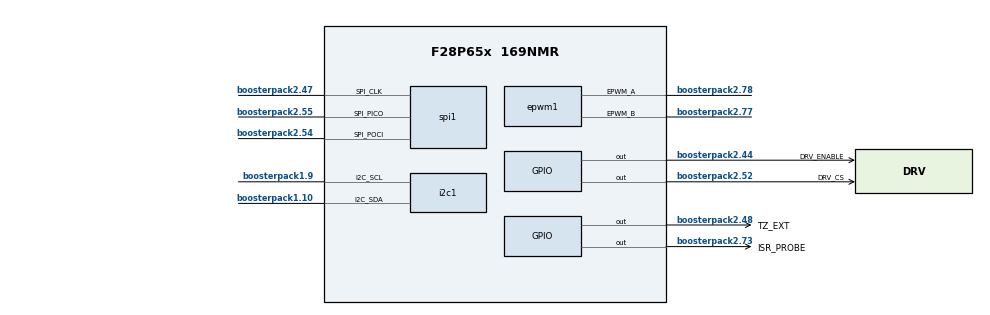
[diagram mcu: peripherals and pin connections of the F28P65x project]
/**
 *
 * @cliArgs --board "/boards/LAUNCHXL_F28P65X" --device "F28P65x" --part "F28P65x_169NMR" --package "169NMR" --context "CPU1" --product "C2000WARE@26.01.00.00"
 * @versions {"tool":"1.28.0+4696"}
 */

/**
 * Import the modules used in this configuration.
 */
const adc            = scripting.addModule("/driverlib/adc.js", {}, false);
const adc1           = adc.addInstance();
const adc2           = adc.addInstance();
const adc3           = adc.addInstance();
const analog         = scripting.addModule("/driverlib/analog.js", {}, false);
const analog1        = analog.addInstance();
const asysctl        = scripting.addModule("/driverlib/asysctl.js");
const led            = scripting.addModule("/driverlib/board_components/led", {}, false);
const led1           = led.addInstance();
const led2           = led.addInstance();
const cmpss          = scripting.addModule("/driverlib/cmpss.js", {}, false);
const cmpss1         = cmpss.addInstance();
const cmpss2         = cmpss.addInstance();
const cputimer       = scripting.addModule("/driverlib/cputimer.js", {}, false);
const cputimer1      = cputimer.addInstance();
const device_support = scripting.addModule("/driverlib/device_support.js");
const epwm           = scripting.addModule("/driverlib/epwm.js", {}, false);
const epwm1          = epwm.addInstance();
const epwm2          = epwm.addInstance();
const epwm3          = epwm.addInstance();
const epwmxbar       = scripting.addModule("/driverlib/epwmxbar.js", {}, false);
const epwmxbar1      = epwmxbar.addInstance();
const gpio           = scripting.addModule("/driverlib/gpio.js", {}, false);
const gpio1          = gpio.addInstance();
const gpio2          = gpio.addInstance();
const gpio3          = gpio.addInstance();
const gpio4          = gpio.addInstance();
const i2c            = scripting.addModule("/driverlib/i2c.js", {}, false);
const i2c1           = i2c.addInstance();
const spi            = scripting.addModule("/driverlib/spi.js", {}, false);
const spi1           = spi.addInstance();
const sysctl         = scripting.addModule("/driverlib/sysctl.js");

/**
 * Write custom configuration values to the imported modules.
 */
adc1.$name               = "myADC0";
adc1.adcClockPrescaler   = "ADC_CLK_DIV_4_0";
adc1.soc0Trigger         = "ADC_TRIGGER_EPWM1_SOCA";
adc1.soc0SampleWindow    = 20;
adc1.useInterrupts       = false;
adc1.enableTDMA          = false;
adc1.enabledInts         = ["ADC_INT_NUMBER1"];
adc1.enableInterrupt1    = true;
adc1.interruptPulseMode  = "ADC_PULSE_END_OF_CONV";
adc1.soc0Channel         = "ADC_CH_ADCIN15";
adc1.soc1Channel         = "ADC_CH_ADCIN8";
adc1.soc2Channel         = "ADC_CH_ADCIN10";
adc1.soc1Trigger         = "ADC_TRIGGER_EPWM1_SOCA";
adc1.soc2Trigger         = "ADC_TRIGGER_EPWM1_SOCA";
adc1.soc1SampleWindow    = 20;
adc1.soc2SampleWindow    = 20;
adc1.enabledSOCs         = ["ADC_SOC_NUMBER0","ADC_SOC_NUMBER1","ADC_SOC_NUMBER2","ADC_SOC_NUMBER3"];
adc1.interrupt1SOCSource = "ADC_INT_TRIGGER_EOC3";
adc1.soc3Channel         = "ADC_CH_ADCIN5";
adc1.soc3Trigger         = "ADC_TRIGGER_EPWM1_SOCA";
adc1.soc3SampleWindow    = 20;

adc2.$name             = "myADC1";
adc2.adcBase           = "ADCB_BASE";
adc2.adcClockPrescaler = "ADC_CLK_DIV_4_0";
adc2.useInterrupts     = false;
adc2.enabledSOCs       = ["ADC_SOC_NUMBER0","ADC_SOC_NUMBER1"];
adc2.soc0Channel       = "ADC_CH_ADCIN3";
adc2.soc1Channel       = "ADC_CH_ADCIN6";
adc2.soc0Trigger       = "ADC_TRIGGER_EPWM1_SOCA";
adc2.soc1Trigger       = "ADC_TRIGGER_EPWM1_SOCA";
adc2.soc0SampleWindow  = 20;
adc2.soc1SampleWindow  = 20;

adc3.$name                      = "myADC2";
adc3.adcBase                    = "ADCC_BASE";
adc3.adcClockPrescaler          = "ADC_CLK_DIV_4_0";
adc3.useInterrupts              = false;
adc3.enabledSOCs                = ["ADC_SOC_NUMBER0"];
adc3.soc0Channel                = "ADC_CH_ADCIN5";
adc3.soc0Trigger                = "ADC_TRIGGER_EPWM1_SOCA";
adc3.soc0SampleWindow           = 20;
adc3.enabledPPBs                = ["ADC_PPB_NUMBER1"];
adc3.ppb1Name                   = "PHASE_C_CURRENT_LIMIT";
adc3.ppb1EventEnable            = ["ADC_EVT_TRIPHI","ADC_EVT_TRIPLO"];
adc3.ppb1HighTripLimit          = 3584;
adc3.ppb1LowTripLimit           = 512;
adc3.ppb1EnablePPBEventCBCClear = true;

led1.$hardware              = system.deviceData.board.components.LED4;
led1.$name                  = "LED_CPU1";
led1.gpio.writeInitialValue = true;
led1.gpio.initialValue      = 1;

led2.$name                  = "LED_CPU2";
led2.$hardware              = system.deviceData.board.components.LED5;
led2.gpio.writeInitialValue = true;
led2.gpio.initialValue      = 1;
led2.gpio.controllerCore    = "GPIO_CORE_CPU2";

const divider8       = system.clockTree["EPWMCLKDIV"];
divider8.divideValue = 1;

cmpss1.$name                = "PHASE_A_CURRENT_CMPSS";
cmpss1.cmpssBase            = "CMPSS7_BASE";
cmpss1.enableModule         = true;
cmpss1.hysteresisVal        = "1";
cmpss1.highCTRIPOUT         = "CMPSS_TRIPOUT_FILTER";
cmpss1.highCTRIP            = "CMPSS_TRIP_FILTER";
cmpss1.dacValHigh           = 3584;
cmpss1.initFilterHigh       = true;
cmpss1.clearFilterLatchHigh = true;
cmpss1.samplePrescaleHigh   = 32;
cmpss1.sampleWindowHigh     = 32;
cmpss1.thresholdHigh        = 30;
cmpss1.asysCMPHPMXSELValue  = "1";
cmpss1.lowCompInvert        = true;
cmpss1.lowCTRIPOUT          = "CMPSS_TRIPOUT_FILTER";
cmpss1.lowCTRIP             = "CMPSS_TRIP_FILTER";
cmpss1.dacValLow            = 512;
cmpss1.initFilterLow        = true;
cmpss1.clearFilterLatchLow  = true;
cmpss1.samplePrescaleLow    = 32;
cmpss1.sampleWindowLow      = 32;
cmpss1.thresholdLow         = 30;
cmpss1.asysCMPLPMXSELValue  = "1";

cmpss2.$name                = "PHASE_B_CURRENT_CMPSS";
cmpss2.cmpssBase            = "CMPSS8_BASE";
cmpss2.enableModule         = true;
cmpss2.hysteresisVal        = "1";
cmpss2.highCTRIPOUT         = "CMPSS_TRIPOUT_FILTER";
cmpss2.highCTRIP            = "CMPSS_TRIP_FILTER";
cmpss2.dacValHigh           = 3584;
cmpss2.initFilterHigh       = true;
cmpss2.clearFilterLatchHigh = true;
cmpss2.samplePrescaleHigh   = 32;
cmpss2.sampleWindowHigh     = 32;
cmpss2.thresholdHigh        = 30;
cmpss2.asysCMPHPMXSELValue  = "1";
cmpss2.lowCompInvert        = true;
cmpss2.lowCTRIPOUT          = "CMPSS_TRIPOUT_FILTER";
cmpss2.lowCTRIP             = "CMPSS_TRIP_FILTER";
cmpss2.dacValLow            = 512;
cmpss2.initFilterLow        = true;
cmpss2.clearFilterLatchLow  = true;
cmpss2.samplePrescaleLow    = 32;
cmpss2.sampleWindowLow      = 32;
cmpss2.thresholdLow         = 30;
cmpss2.asysCMPLPMXSELValue  = "1";

analog1.$name            = "myANALOGPinMux0";
adc1.analog              = analog1;
analog1.useCase          = "CUSTOM";
adc2.analog              = analog1;
adc3.analog              = analog1;
analog1.useInterfacePins = ["A10, GPIO213","A15/B15/C15","A5","A8, GPIO211","B3","B6, GPIO207","C5, GPIO204"];
cmpss1.analog            = analog1;
cmpss2.analog            = analog1;

cputimer1.cputimerBase  = "CPUTIMER1_BASE";
cputimer1.timerPeriod   = 4294967295;
cputimer1.emulationMode = "CPUTIMER_EMULATIONMODE_RUNFREE";
cputimer1.startTimer    = true;
cputimer1.$name         = "ISR_CYCLE_TIMER";

epwm1.$name                                                      = "PWM_TB";
epwm1.$hardware                                                  = system.deviceData.board.components.BP_SITE_2.subComponents.PWM_LOC2;
epwm1.epwmTimebase_counterMode                                   = "EPWM_COUNTER_MODE_UP_DOWN";
epwm1.epwmTimebase_hsClockDiv                                    = "EPWM_HSCLOCK_DIVIDER_1";
epwm1.epwmTimebase_emulationMode                                 = "EPWM_EMULATION_FREE_RUN";
epwm1.epwmActionQualifier_EPWM_AQ_OUTPUT_A_ON_TIMEBASE_UP_CMPA   = "EPWM_AQ_OUTPUT_HIGH";
epwm1.epwmActionQualifier_EPWM_AQ_OUTPUT_A_ON_TIMEBASE_DOWN_CMPA = "EPWM_AQ_OUTPUT_LOW";
epwm1.epwmDeadband_delayRED                                      = 200;
epwm1.epwmDeadband_delayFED                                      = 200;
epwm1.epwmDeadband_enableFED                                     = true;
epwm1.epwmDeadband_polarityFED                                   = "EPWM_DB_POLARITY_ACTIVE_LOW";
epwm1.epwmDeadband_enableRED                                     = true;
epwm1.epwmDeadband_redShadowMode                                 = true;
epwm1.epwmDeadband_fedShadowMode                                 = true;
epwm1.epwmTripZone_EPWM_TZ_ACTION_EVENT_TZA                      = "EPWM_TZ_ACTION_LOW";
epwm1.epwmTripZone_EPWM_TZ_ACTION_EVENT_TZB                      = "EPWM_TZ_ACTION_LOW";
epwm1.epwmTripZone_oneShotSource                                 = ["EPWM_TZ_SIGNAL_OSHT1"];
epwm1.epwmTripZone_cbcSource                                     = ["EPWM_TZ_SIGNAL_CBC6"];
epwm1.epwmEventTrigger_EPWM_SOC_A_triggerEnable                  = true;
epwm1.epwmEventTrigger_EPWM_SOC_A_triggerEventPrescalar          = "1";
epwm1.epwmTimebase_period                                        = 5000;
epwm1.epwmCounterCompare_cmpA                                    = 2500;
epwm1.epwmTimebase_syncOutPulseMode                              = ["EPWM_SYNC_OUT_PULSE_ON_CNTR_ZERO"];
epwm1.epwm.$assign                                               = "EPWM1";
epwm1.epwm.epwm_aPin.$assign                                     = "boosterpack2.78";
epwm1.epwm.epwm_bPin.$assign                                     = "boosterpack2.77";

epwm2.$name                                                      = "PWM_PHASE_A";
epwm2.$hardware                                                  = system.deviceData.board.components.BP_SITE_2.subComponents.PWM_LOC1;
epwm2.epwmTimebase_emulationMode                                 = "EPWM_EMULATION_FREE_RUN";
epwm2.epwmTimebase_hsClockDiv                                    = "EPWM_HSCLOCK_DIVIDER_1";
epwm2.epwmTimebase_period                                        = 5000;
epwm2.epwmTimebase_counterMode                                   = "EPWM_COUNTER_MODE_UP_DOWN";
epwm2.epwmTimebase_phaseEnable                                   = true;
epwm2.epwmCounterCompare_cmpA                                    = 2500;
epwm2.epwmActionQualifier_EPWM_AQ_OUTPUT_A_ON_TIMEBASE_UP_CMPA   = "EPWM_AQ_OUTPUT_HIGH";
epwm2.epwmActionQualifier_EPWM_AQ_OUTPUT_A_ON_TIMEBASE_DOWN_CMPA = "EPWM_AQ_OUTPUT_LOW";
epwm2.epwmDeadband_polarityFED                                   = "EPWM_DB_POLARITY_ACTIVE_LOW";
epwm2.epwmDeadband_enableRED                                     = true;
epwm2.epwmDeadband_enableFED                                     = true;
epwm2.epwmDeadband_redShadowMode                                 = true;
epwm2.epwmDeadband_fedShadowMode                                 = true;
epwm2.epwmDeadband_delayRED                                      = 200;
epwm2.epwmDeadband_delayFED                                      = 200;
epwm2.epwmTripZone_EPWM_TZ_ACTION_EVENT_TZA                      = "EPWM_TZ_ACTION_LOW";
epwm2.epwmTripZone_EPWM_TZ_ACTION_EVENT_TZB                      = "EPWM_TZ_ACTION_LOW";
epwm2.epwmTripZone_oneShotSource                                 = ["EPWM_TZ_SIGNAL_OSHT1"];
epwm2.epwmTripZone_cbcSource                                     = ["EPWM_TZ_SIGNAL_CBC6"];
epwm2.epwmTimebase_counterModeAfterSync                          = "EPWM_COUNT_MODE_UP_AFTER_SYNC";

epwm3.$name                                                      = "PWM_PHASE_C";
epwm3.$hardware                                                  = system.deviceData.board.components.BP_SITE_2.subComponents.PWM_LOC3;
epwm3.epwmTimebase_emulationMode                                 = "EPWM_EMULATION_FREE_RUN";
epwm3.epwmTimebase_hsClockDiv                                    = "EPWM_HSCLOCK_DIVIDER_1";
epwm3.epwmTimebase_period                                        = 5000;
epwm3.epwmTimebase_counterMode                                   = "EPWM_COUNTER_MODE_UP_DOWN";
epwm3.epwmTimebase_phaseEnable                                   = true;
epwm3.epwmCounterCompare_cmpA                                    = 2500;
epwm3.epwmActionQualifier_EPWM_AQ_OUTPUT_A_ON_TIMEBASE_UP_CMPA   = "EPWM_AQ_OUTPUT_HIGH";
epwm3.epwmActionQualifier_EPWM_AQ_OUTPUT_A_ON_TIMEBASE_DOWN_CMPA = "EPWM_AQ_OUTPUT_LOW";
epwm3.epwmDeadband_polarityFED                                   = "EPWM_DB_POLARITY_ACTIVE_LOW";
epwm3.epwmDeadband_enableRED                                     = true;
epwm3.epwmDeadband_enableFED                                     = true;
epwm3.epwmDeadband_redShadowMode                                 = true;
epwm3.epwmDeadband_fedShadowMode                                 = true;
epwm3.epwmDeadband_delayRED                                      = 200;
epwm3.epwmDeadband_delayFED                                      = 200;
epwm3.epwmTripZone_EPWM_TZ_ACTION_EVENT_TZA                      = "EPWM_TZ_ACTION_LOW";
epwm3.epwmTripZone_EPWM_TZ_ACTION_EVENT_TZB                      = "EPWM_TZ_ACTION_LOW";
epwm3.epwmTripZone_oneShotSource                                 = ["EPWM_TZ_SIGNAL_OSHT1"];
epwm3.epwmTripZone_cbcSource                                     = ["EPWM_TZ_SIGNAL_CBC6"];
epwm3.epwmTimebase_counterModeAfterSync                          = "EPWM_COUNT_MODE_UP_AFTER_SYNC";

epwmxbar1.$name      = "POWER_TRIP_XBAR";
epwmxbar1.tripInput  = "XBAR_TRIP7";
epwmxbar1.muxesUsed  = ["XBAR_MUX01","XBAR_MUX12","XBAR_MUX13","XBAR_MUX14","XBAR_MUX15"];
epwmxbar1.mux1Config = "XBAR_EPWM_MUX01_ADCCEVT1";

gpio1.$name             = "ISR_PROBE";
gpio1.direction         = "GPIO_DIR_MODE_OUT";
gpio1.writeInitialValue = true;
gpio1.gpioPin.$assign   = "boosterpack2.73";

gpio2.$name             = "TZ_EXT";
gpio2.padConfig         = "PULLUP";
gpio2.qualMode          = "GPIO_QUAL_ASYNC";
gpio2.writeInitialValue = true;
gpio2.initialValue      = 1;
gpio2.gpioPin.$assign   = "boosterpack2.48";

gpio3.$name             = "DRV_ENABLE";
gpio3.direction         = "GPIO_DIR_MODE_OUT";
gpio3.writeInitialValue = true;
gpio3.gpioPin.$assign   = "boosterpack2.44";

gpio4.$name             = "DRV_CS";
gpio4.direction         = "GPIO_DIR_MODE_OUT";
gpio4.writeInitialValue = true;
gpio4.initialValue      = 1;
gpio4.gpioPin.$assign   = "boosterpack2.52";

i2c1.$name                  = "AS5600_I2C";
i2c1.$hardware              = system.deviceData.board.components.BP_SITE_1.subComponents.I2C;
i2c1.bitCount               = "I2C_BITCOUNT_8";
i2c1.useInterrupts          = false;
i2c1.emulationMode          = "I2C_EMULATION_FREE_RUN";
i2c1.useFifo                = false;
i2c1.i2c.$assign            = "I2CA";
i2c1.i2c.i2c_sdaPin.$assign = "boosterpack1.10";
i2c1.i2c.i2c_sclPin.$assign = "boosterpack1.9";

spi1.$name                   = "DRV_SPI";
spi1.useCase                 = "3-WIRE CONTROLLER";
spi1.mode                    = "SPI_MODE_CONTROLLER";
spi1.emulationMode           = "SPI_EMULATION_FREE_RUN";
spi1.useInterrupts           = false;
spi1.bitRate                 = 400000;
spi1.picoQual.$name          = "myGPIOQUAL0";
spi1.pociQual.$name          = "myGPIOQUAL1";
spi1.clkQual.$name           = "myGPIOQUAL2";
spi1.spi.$assign             = "SPID";
spi1.spi.spi_picoPin.$assign = "boosterpack2.55";
spi1.spi.spi_pociPin.$assign = "boosterpack2.54";
spi1.spi.spi_clkPin.$assign  = "boosterpack2.47";

sysctl.cpuSel_SCIA = "SYSCTL_CPUSEL_CPU2";

/**
 * Pinmux solution for unlocked pins/peripherals. This ensures that minor changes to the automatic solver in a future
 * version of the tool will not impact the pinmux you originally saw.  These lines can be completely deleted in order to
 * re-solve from scratch.
 */
led1.gpio.gpioPin.$suggestSolution                 = "boosterpack1.13";
led2.gpio.gpioPin.$suggestSolution                 = "boosterpack2.53";
analog1.analog.$suggestSolution                    = "ANALOG";
analog1.analog["a10, gpio213Pin"].$suggestSolution = "boosterpack2.67";
analog1.analog["a15/b15/c15Pin"].$suggestSolution  = "boosterpack2.63";
analog1.analog.a5Pin.$suggestSolution              = "boosterpack2.42";
analog1.analog["a8, gpio211Pin"].$suggestSolution  = "boosterpack2.64";
analog1.analog.b3Pin.$suggestSolution              = "boosterpack2.65";
analog1.analog["b6, gpio207Pin"].$suggestSolution  = "boosterpack2.68";
analog1.analog["c5, gpio204Pin"].$suggestSolution  = "boosterpack2.66";
epwm2.epwm.$suggestSolution                        = "EPWM2";
epwm2.epwm.epwm_aPin.$suggestSolution              = "boosterpack2.80";
epwm2.epwm.epwm_bPin.$suggestSolution              = "boosterpack2.79";
epwm3.epwm.$suggestSolution                        = "EPWM8";
epwm3.epwm.epwm_aPin.$suggestSolution              = "boosterpack2.76";
epwm3.epwm.epwm_bPin.$suggestSolution              = "boosterpack2.75";
